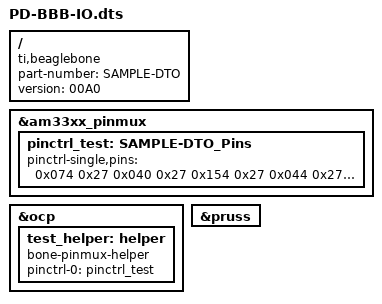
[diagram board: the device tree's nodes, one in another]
/dts-v1/;
/plugin/;

/{
   compatible = "ti,beaglebone", "ti,beaglebone-black";
   part-number = "SAMPLE-DTO";
   version = "00A0";

   fragment@0 {
      target = <&am33xx_pinmux>;
      __overlay__ {
         pinctrl_test: SAMPLE-DTO_Pins {
            pinctrl-single,pins = <
               /* OUTPUT  GPIO(mode7) 0x0f no pullup/pulldown */
               /* INPUT   GPIO(mode7) 0x27 pulldown, 0x37 pullup, 0x2f no pullup/down */


               /********************************************************************************/
               /* Inputs with pulldown: /*
               0x070 0x27 /* P9_11 */
               0x074 0x27 /* P9_13 */
               0x040 0x27 /* P9_15 */
               0x154 0x27 /* P9_21 */
               0x044 0x27 /* P9_23 */
               0x1b4 0x27 /* P9_41 */

               /* Outputs, no pull*/
               0x078 0x0f /* P9_12 */
               0x048 0x0f /* P9_14 */
               0x04c 0x0f /* P9_16 */
               0x150 0x0f /* P9_22 */
               0x1a4 0x0f /* P9_27 */
               0x198 0x0f /* P9_30 */
               0x164 0x0f /* P9_42 */

               /* Unused */
               /* 0x15c 0x0f */   /* P9_17 */
               /* 0x158 0x0f */  /* P9_18 */
               /* 0x184 0x0f */   /* P9_24 */
               /* 0x180 0x0f */   /* P9_26 */


               /********************************************************************************/
               /* These 2 as inputs always as they share a physical connection with 41 and 42 */
               0x1a8 0x2f  /* P9_42 */
               0x1a0 0x2f  /* P9_42 */

            >;
         };
      };
   };

   fragment@1 {
      target = <&ocp>;
      __overlay__ {
         test_helper: helper {
            compatible = "bone-pinmux-helper";
            pinctrl-names = "default";
            pinctrl-0 = <&pinctrl_test>;
            status = "okay";
         };
      };
   };

   fragment@2{
      target = <&pruss>;
      __overlay__ {
         status = "okay";
      };
   };

};
